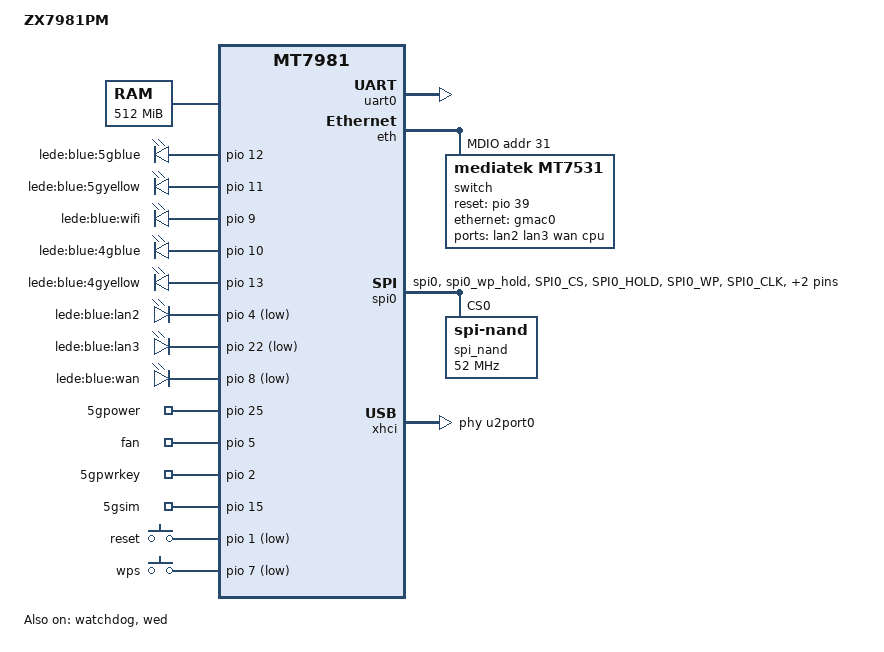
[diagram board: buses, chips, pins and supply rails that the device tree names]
/dts-v1/;
#include "mt7981.dtsi"

#include <dt-bindings/input/input.h>

/ {
	model = "ZX7981PM";
	compatible = "ZX7981PM";
	chosen {
		bootargs = "console=ttyS0,115200n1 loglevel=8  \
				earlycon=uart8250,mmio32,0x11002000";
	};

	memory {
		// fpga ddr2: 128MB*2
		reg = <0 0x40000000 0 0x20000000>;
	};

	gpio-leds {
		compatible = "gpio-leds";

		5gblue {
			label = "lede:blue:5gblue";
			gpios = <&pio 12 0>;
			linux,default-trigger = "none";
			default-state = "off";
		};

		5gyellow {
			label = "lede:blue:5gyellow";
			gpios = <&pio 11 0>;
			linux,default-trigger = "none";
			default-state = "off";
		};

		wifi {
			label = "lede:blue:wifi";
			gpios = <&pio 9 0>;
			linux,default-trigger = "none";
			default-state = "off";
		};

		4gblue {
			label = "lede:blue:4gblue";
			gpios = <&pio 10 0>;
			linux,default-trigger = "none";
			default-state = "off";
		};

		4gyellow {
			label = "lede:blue:4gyellow";
			gpios = <&pio 13 0>;
			linux,default-trigger = "none";
			default-state = "off";
		};

		lan2 {
			label = "lede:blue:lan2";
			gpios = <&pio 4 1>;
			linux,default-trigger = "none";
			default-state = "off";
		};

		lan3 {
			label = "lede:blue:lan3";
			gpios = <&pio 22 1>;
			linux,default-trigger = "none";
			default-state = "off";
		};

		wan {
			label = "lede:blue:wan";
			gpios = <&pio 8 1>;
			linux,default-trigger = "none";
			default-state = "off";
		};
	};

	gpio-export {
		compatible = "gpio-export";
		5gpower {
			gpio-export,name = "5gpower";
			gpio-export,output = <0>; // OUT_INIT_LOW
			gpios = <&pio 25 0>;    // GPIO 25, ACTIVE_LOW
		};

		fan {
			gpio-export,name = "fan";
			gpio-export,output = <1>; // OUT_INIT_LOW
			gpios = <&pio 5 0>;    // GPIO 5, ACTIVE_LOW
		};

		5gpwrkey {
			gpio-export,name = "5gpwrkey";
			gpio-export,output = <0>; // OUT_INIT_LOW
			gpios = <&pio 2 0>;    // GPIO 2, ACTIVE_LOW
		};

		5gsim {
			gpio-export,name = "5gsim";
			gpio-export,output = <1>; // OUT_INIT_LOW
			gpios = <&pio 15 0>;    // GPIO 15, ACTIVE_LOW
		};

	};

	gpio-keys {
		compatible = "gpio-keys";
		#address-cells = <1>;
		#size-cells = <0>;
		poll-interval = <20>;

		reset {
			label = "reset";
			gpios = <&pio 1 1>;
			linux,code = <KEY_RESTART>;
		};

		wps {
			label = "wps";
			gpios = <&pio 7 1>;
			linux,code = <KEY_WPS_BUTTON>;
		};
	};

	nmbm_spim_nand {
		compatible = "generic,nmbm";

		#address-cells = <1>;
		#size-cells = <1>;

		lower-mtd-device = <&spi_nand>;
		forced-create;

		partitions {
			compatible = "fixed-partitions";
			#address-cells = <1>;
			#size-cells = <1>;

			partition@0 {
				label = "BL2";
				reg = <0x00000 0x0100000>;
			};

			partition@100000 {
				label = "u-boot-env";
				reg = <0x0100000 0x0080000>;
			};

			factory: partition@180000 {
				label = "Factory";
				reg = <0x180000 0x0200000>;
			};

			partition@380000 {
				label = "FIP";
				reg = <0x380000 0x0200000>;
			};

			partition@580000 {
				label = "woem";
				reg = <0x580000 0xa0000>;
			};

			partition@620000 {
				label = "ubi";
				reg = <0x620000 0x3800000>;
			};

			partition@3E20000 {
				label = "ubi2";
				reg = <0x3E20000 0x3800000>;
			};

			partition@7620000 {
				label = "wtinfo";
				reg = <0x7620000 0x60000>;
			};

			partition@7680000 {
				label = "nvram";
				reg = <0x7680000 0x60000>;
			};
		};
	};
};

&uart0 {
	status = "okay";
};

&watchdog {
	status = "okay";
};

&eth {
        status = "okay";

        gmac0: mac@0 {
                compatible = "mediatek,eth-mac";
                reg = <0>;
                phy-mode = "2500base-x";

                fixed-link {
                        speed = <2500>;
                        full-duplex;
                        pause;
                };
        };

        mdio: mdio-bus {
                #address-cells = <1>;
                #size-cells = <0>;

		switch@0 {
                        compatible = "mediatek,mt7531";
                        reg = <31>;
                        reset-gpios = <&pio 39 0>;

                        ports {
                                #address-cells = <1>;
                                #size-cells = <0>;

                                port@1 {
                                        reg = <1>;
                                        label = "lan2";
                                };

                                port@2 {
                                        reg = <2>;
                                        label = "lan3";
                                };

                        	port@5 {
                                	reg = <5>;
	                                label = "wan";
        	                        phy-mode = "2500base-x";

                	                fixed-link {
                        	                speed = <2500>;
                                	        full-duplex;
                                        	pause;
	                                };
        	                };
 

                                port@6 {
                                        reg = <6>;
                                        label = "cpu";
                                        ethernet = <&gmac0>;
                                        phy-mode = "2500base-x";

                                        fixed-link {
                                                speed = <2500>;
                                                full-duplex;
                                                pause;
                                        };
                                };
                        };
                };
        };
};

&hnat {
	mtketh-wan = "wan";
	mtketh-lan = "lan";
	mtketh-max-gmac = <1>;
	status = "disabled";
};

&spi0 {
	pinctrl-names = "default";
	pinctrl-0 = <&spi0_flash_pins>;
	status = "okay";
	spi_nand: spi_nand@0 {
		#address-cells = <1>;
		#size-cells = <1>;
		compatible = "spi-nand";
		reg = <0>;
		spi-max-frequency = <52000000>;
		spi-tx-bus-width = <4>;
		spi-rx-bus-width = <4>;
	};
};

&pio {
	spi0_flash_pins: spi0-pins {
		mux {
			function = "spi";
			groups = "spi0", "spi0_wp_hold";
		};

		conf-pu {
			pins = "SPI0_CS", "SPI0_HOLD", "SPI0_WP";
			drive-strength = <MTK_DRIVE_8mA>;
			bias-pull-up = <MTK_PUPD_SET_R1R0_11>;
		};

		conf-pd {
			pins = "SPI0_CLK", "SPI0_MOSI", "SPI0_MISO";
			drive-strength = <MTK_DRIVE_8mA>;
			bias-pull-down = <MTK_PUPD_SET_R1R0_11>;
		};
	};
};

&xhci {
	mediatek,u3p-dis-msk = <0x0>;
	phys = <&u2port0 PHY_TYPE_USB2>,
	       <&u3port0 PHY_TYPE_USB3>;
        status = "okay";
};

&wed {
	dy_txbm_enable = "true";
	dy_txbm_budget = <8>;
	txbm_init_sz = <8>;
	txbm_max_sz = <32>;
	status = "okay";
};
